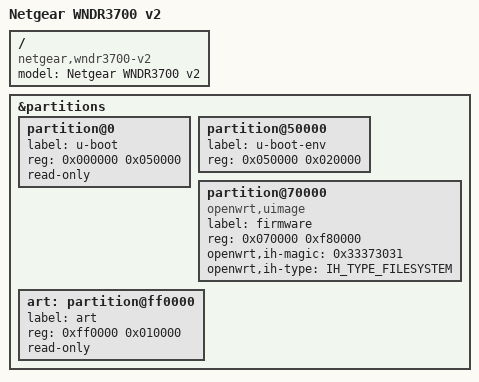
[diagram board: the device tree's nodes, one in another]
// SPDX-License-Identifier: GPL-2.0-or-later OR MIT

#include "ar7161_netgear_wndr.dtsi"

/ {
	compatible = "netgear,wndr3700-v2", "qca,ar7161";
	model = "Netgear WNDR3700 v2";
};

&partitions {
	partition@0 {
		label = "u-boot";
		reg = <0x000000 0x050000>;
		read-only;
	};

	partition@50000 {
		label = "u-boot-env";
		reg = <0x050000 0x020000>;
	};

	partition@70000 {
		label = "firmware";
		reg = <0x070000 0xf80000>;
		compatible = "openwrt,uimage", "denx,uimage";
		openwrt,ih-magic = <0x33373031>;
		openwrt,ih-type = <IH_TYPE_FILESYSTEM>;
	};

	art: partition@ff0000 {
		label = "art";
		reg = <0xff0000 0x010000>;
		read-only;
	};
};
